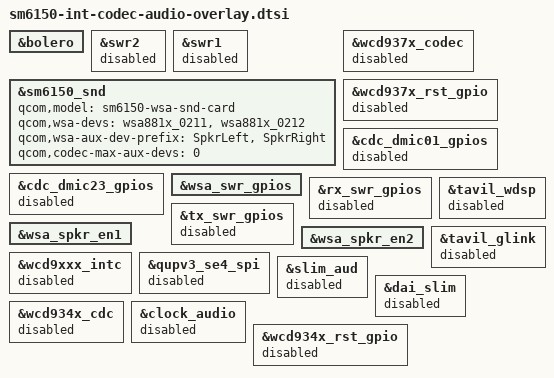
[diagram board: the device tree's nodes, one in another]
/*
 * Copyright (c) 2018, The Linux Foundation. All rights reserved.
 * Copyright (c) 2022 Qualcomm Innovation Center, Inc. All rights reserved.
 *
 * This program is free software; you can redistribute it and/or modify
 * it under the terms of the GNU General Public License version 2 and
 * only version 2 as published by the Free Software Foundation.
 *
 * This program is distributed in the hope that it will be useful,
 * but WITHOUT ANY WARRANTY; without even the implied warranty of
 * MERCHANTABILITY or FITNESS FOR A PARTICULAR PURPOSE.  See the
 * GNU General Public License for more details.
 */

#include "sm6150-audio-overlay.dtsi"

&bolero {
	status = "okay";
};

&swr2 {
	status = "disabled";
};

&swr1 {
	status = "disabled";
};

&sm6150_snd {
	qcom,model = "sm6150-wsa-snd-card";
	qcom,wsa-devs = <&wsa881x_0211>, <&wsa881x_0212>;
	qcom,wsa-aux-dev-prefix = "SpkrLeft", "SpkrRight";
	qcom,codec-max-aux-devs = <0>;
};

&wcd937x_codec {
	status = "disabled";
};

&wcd937x_rst_gpio {
	status  = "disabled";
};

&cdc_dmic01_gpios {
	status = "disabled";
};

&cdc_dmic23_gpios {
	status = "disabled";
};

&wsa_swr_gpios {
	status = "okay";
};

&rx_swr_gpios {
	status = "disabled";
};

&tx_swr_gpios {
	status = "disabled";
};

&wsa_spkr_en1 {
	status = "okay";
};

&wsa_spkr_en2 {
	status = "okay";
};

&wcd9xxx_intc {
	status = "disabled";
};

&qupv3_se4_spi {
	status = "disabled";
};

&tavil_wdsp {
	status = "disabled";
};

&tavil_glink {
	status = "disabled";
};

&slim_aud {
	status = "disabled";
};

&dai_slim {
	status = "disabled";
};

&wcd934x_cdc {
	status = "disabled";
};

&clock_audio {
	status = "disabled";
};

&wcd934x_rst_gpio {
	status = "disabled";
};
